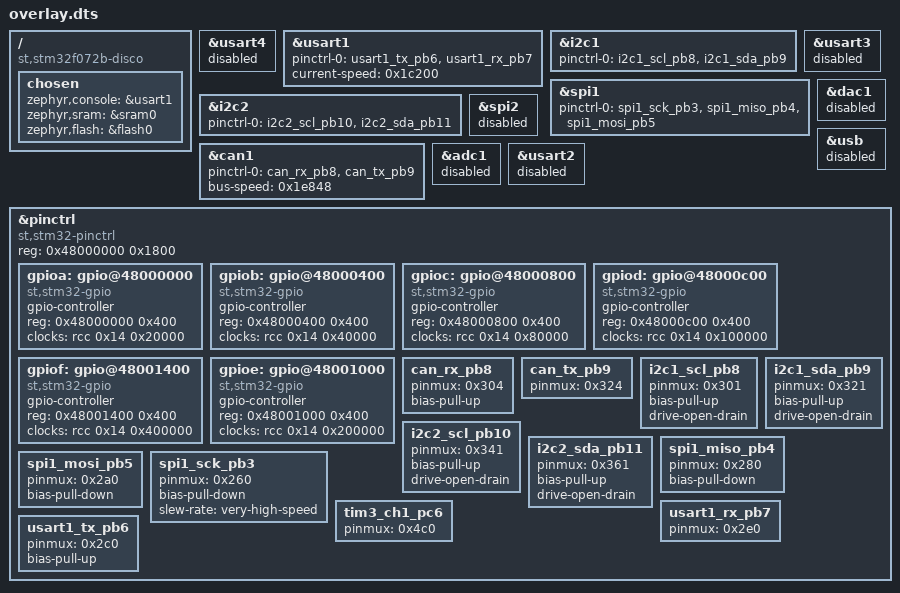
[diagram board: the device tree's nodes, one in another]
/ {
	compatible = "st,stm32f072b-disco";
	chosen {
		zephyr,console = &usart1;
		zephyr,sram = &sram0;
		zephyr,flash = &flash0;
	};
};
&usart4{
	status = "disabled";
};
&usart1{
	status = "okay";
	pinctrl-0 = < &usart1_tx_pb6 &usart1_rx_pb7 >;
	pinctrl-names = "default";
	current-speed = < 0x1c200 >;
};
&i2c1{
	status = "okay";
	pinctrl-0 = < &i2c1_scl_pb8 &i2c1_sda_pb9 >;
	pinctrl-names = "default";
};
&usart3{
	status = "disabled";
};
&spi1{
	status = "okay";
	pinctrl-0 = < &spi1_sck_pb3 &spi1_miso_pb4 &spi1_mosi_pb5 >;
	pinctrl-names = "default";
};
&i2c2{
	status = "okay";
	pinctrl-0 = < &i2c2_scl_pb10 &i2c2_sda_pb11 >;
	pinctrl-names = "default";
};
&can1{
	status = "okay";
	pinctrl-0 = < &can_rx_pb8 &can_tx_pb9 >;
	pinctrl-names = "default";
	bus-speed = < 0x1e848 >;
};
&dac1{
	status = "disabled";
};
&spi2{
	status = "disabled";
};
&usb{
	status = "disabled";
};
&adc1{
	status = "disabled";
};
&usart2{
	status = "disabled";
};
&pinctrl{
	compatible = "st,stm32-pinctrl";
	#address-cells = < 0x1 >;
	#size-cells = < 0x1 >;
	reg = < 0x48000000 0x1800 >;
	gpioa: gpio@48000000 {
		compatible = "st,stm32-gpio";
		gpio-controller;
		#gpio-cells = < 0x2 >;
		reg = < 0x48000000 0x400 >;
		clocks = < &rcc 0x14 0x20000 >;
	};
	gpiob: gpio@48000400 {
		compatible = "st,stm32-gpio";
		gpio-controller;
		#gpio-cells = < 0x2 >;
		reg = < 0x48000400 0x400 >;
		clocks = < &rcc 0x14 0x40000 >;
	};
	gpioc: gpio@48000800 {
		compatible = "st,stm32-gpio";
		gpio-controller;
		#gpio-cells = < 0x2 >;
		reg = < 0x48000800 0x400 >;
		clocks = < &rcc 0x14 0x80000 >;
	};
	gpiod: gpio@48000c00 {
		compatible = "st,stm32-gpio";
		gpio-controller;
		#gpio-cells = < 0x2 >;
		reg = < 0x48000c00 0x400 >;
		clocks = < &rcc 0x14 0x100000 >;
	};
	gpiof: gpio@48001400 {
		compatible = "st,stm32-gpio";
		gpio-controller;
		#gpio-cells = < 0x2 >;
		reg = < 0x48001400 0x400 >;
		clocks = < &rcc 0x14 0x400000 >;
	};
	gpioe: gpio@48001000 {
		compatible = "st,stm32-gpio";
		gpio-controller;
		#gpio-cells = < 0x2 >;
		reg = < 0x48001000 0x400 >;
		clocks = < &rcc 0x14 0x200000 >;
	};
	can_rx_pb8: can_rx_pb8 {
		pinmux = < 0x304 >;
		bias-pull-up;
	};
	can_tx_pb9: can_tx_pb9 {
		pinmux = < 0x324 >;
	};
	i2c1_scl_pb8: i2c1_scl_pb8 {
		pinmux = < 0x301 >;
		bias-pull-up;
		drive-open-drain;
	};
	i2c2_scl_pb10: i2c2_scl_pb10 {
		pinmux = < 0x341 >;
		bias-pull-up;
		drive-open-drain;
	};
	i2c1_sda_pb9: i2c1_sda_pb9 {
		pinmux = < 0x321 >;
		bias-pull-up;
		drive-open-drain;
	};
	i2c2_sda_pb11: i2c2_sda_pb11 {
		pinmux = < 0x361 >;
		bias-pull-up;
		drive-open-drain;
	};
	spi1_miso_pb4: spi1_miso_pb4 {
		pinmux = < 0x280 >;
		bias-pull-down;
	};
	spi1_mosi_pb5: spi1_mosi_pb5 {
		pinmux = < 0x2a0 >;
		bias-pull-down;
	};
	spi1_sck_pb3: spi1_sck_pb3 {
		pinmux = < 0x260 >;
		bias-pull-down;
		slew-rate = "very-high-speed";
	};
	tim3_ch1_pc6: tim3_ch1_pc6 {
		pinmux = < 0x4c0 >;
	};
	usart1_rx_pb7: usart1_rx_pb7 {
		pinmux = < 0x2e0 >;
	};
	usart1_tx_pb6: usart1_tx_pb6 {
		pinmux = < 0x2c0 >;
		bias-pull-up;
	};
};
